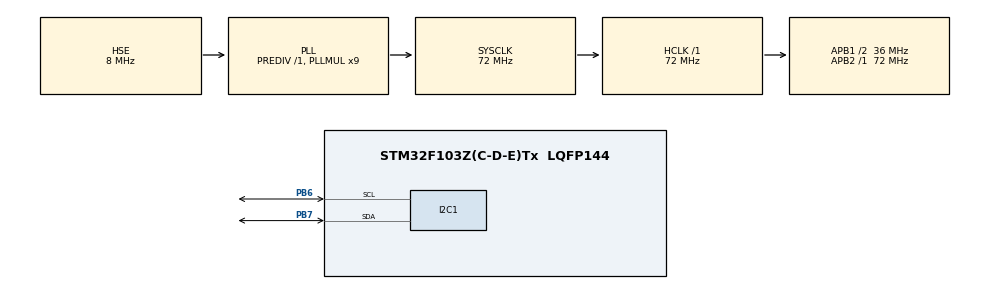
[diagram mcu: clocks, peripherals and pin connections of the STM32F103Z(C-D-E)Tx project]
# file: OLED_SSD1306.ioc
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Mcu.Family=STM32F1
RCC.PLLSourceVirtual=RCC_PLLSOURCE_HSE
RCC.APB1CLKDivider=RCC_HCLK_DIV2
RCC.SYSCLKSource=RCC_SYSCLKSOURCE_PLLCLK
ProjectManager.StackSize=0x400
PA13.Signal=SYS_JTMS-SWDIO
ProjectManager.TargetToolchain=Makefile
RCC.HCLKFreq_Value=72000000
RCC.APB2TimFreq_Value=72000000
PB6.Signal=I2C1_SCL
PB6.Mode=I2C
OSC_IN.Signal=RCC_OSC_IN
RCC.USBFreq_Value=72000000
OSC_OUT.Mode=HSE-External-Oscillator
OSC_OUT.Signal=RCC_OSC_OUT
RCC.AHBFreq_Value=72000000
board=custom
RCC.PLLMUL=RCC_PLL_MUL9
RCC.APB2Freq_Value=72000000
PA14.Mode=Serial_Wire
PB7.Signal=I2C1_SDA
PA13.Mode=Serial_Wire
Mcu.Name=STM32F103Z(C-D-E)Tx
RCC.SYSCLKFreq_VALUE=72000000
Mcu.Package=LQFP144
OSC_IN.Mode=HSE-External-Oscillator
PB7.Mode=I2C
PA14.Signal=SYS_JTCK-SWCLK
ProjectManager.HeapSize=0x200
NVIC.PriorityGroup=NVIC_PRIORITYGROUP_4
RCC.APB1TimFreq_Value=72000000
RCC.APB1Freq_Value=36000000

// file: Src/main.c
/* USER CODE BEGIN Header */
/**
  ******************************************************************************
  * @file           : main.c
  * @brief          : Main program body
  ******************************************************************************
  * @attention
  *
  * <h2><center>&copy; Copyright (c) 2020 STMicroelectronics.
  * All rights reserved.</center></h2>
  *
  * This software component is licensed by ST under BSD 3-Clause license,
  * the "License"; You may not use this file except in compliance with the
  * License. You may obtain a copy of the License at:
  *                        opensource.org/licenses/BSD-3-Clause
  *
  ******************************************************************************
  */
/* USER CODE END Header */

#include "main.h"
#include "i2c.h"
#include "gpio.h"

/* USER CODE BEGIN Includes */
#include "OLED_SSD1306.h"

/* USER CODE END Includes */

void SystemClock_Config(void);

int main(void)
{

  /* MCU Configuration--------------------------------------------------------*/

  /* Reset of all peripherals, Initializes the Flash interface and the Systick. */
  HAL_Init();

  /* Configure the system clock */
  SystemClock_Config();

  /* Initialize all configured peripherals */
  MX_GPIO_Init();
  MX_I2C1_Init();
  /* USER CODE BEGIN 2 */

  OLED_Init();
	OLED_open();
  OLED_clear();

  OLED_Display_String(2, "tinayi");

  /* USER CODE END 2 */

  /* Infinite loop */
  while (1)
  {

    /* USER CODE BEGIN 3 */
    //OLED_Display_Single(0, 0, '5');
  }
  /* USER CODE END 3 */
}

void SystemClock_Config(void)
{
  RCC_OscInitTypeDef RCC_OscInitStruct = {0};
  RCC_ClkInitTypeDef RCC_ClkInitStruct = {0};

  /** Initializes the CPU, AHB and APB busses clocks
  */
  RCC_OscInitStruct.OscillatorType = RCC_OSCILLATORTYPE_HSE;
  RCC_OscInitStruct.HSEState = RCC_HSE_ON;
  RCC_OscInitStruct.HSEPredivValue = RCC_HSE_PREDIV_DIV1;
  RCC_OscInitStruct.HSIState = RCC_HSI_ON;
  RCC_OscInitStruct.PLL.PLLState = RCC_PLL_ON;
  RCC_OscInitStruct.PLL.PLLSource = RCC_PLLSOURCE_HSE;
  RCC_OscInitStruct.PLL.PLLMUL = RCC_PLL_MUL9;
  if (HAL_RCC_OscConfig(&RCC_OscInitStruct) != HAL_OK)
  {
    Error_Handler();
  }
  /** Initializes the CPU, AHB and APB busses clocks
  */
  RCC_ClkInitStruct.ClockType = RCC_CLOCKTYPE_HCLK|RCC_CLOCKTYPE_SYSCLK
                              |RCC_CLOCKTYPE_PCLK1|RCC_CLOCKTYPE_PCLK2;
  RCC_ClkInitStruct.SYSCLKSource = RCC_SYSCLKSOURCE_PLLCLK;
  RCC_ClkInitStruct.AHBCLKDivider = RCC_SYSCLK_DIV1;
  RCC_ClkInitStruct.APB1CLKDivider = RCC_HCLK_DIV2;
  RCC_ClkInitStruct.APB2CLKDivider = RCC_HCLK_DIV1;

  if (HAL_RCC_ClockConfig(&RCC_ClkInitStruct, FLASH_LATENCY_2) != HAL_OK)
  {
    Error_Handler();
  }
}

void Error_Handler(void)
{
}

/************************ (C) COPYRIGHT STMicroelectronics *****END OF FILE****/
